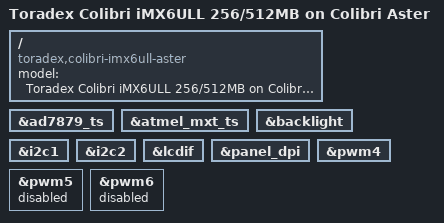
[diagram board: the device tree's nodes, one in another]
// SPDX-License-Identifier: GPL-2.0-or-later OR MIT
/*
 * Copyright 2017-2022 Toradex
 */

/dts-v1/;

#include "imx6ull-colibri-nonwifi.dtsi"
#include "imx6ull-colibri-aster.dtsi"

/ {
	model = "Toradex Colibri iMX6ULL 256/512MB on Colibri Aster";
	compatible = "toradex,colibri-imx6ull-aster",
		     "toradex,colibri-imx6ull",
		     "fsl,imx6ull";
};

&ad7879_ts {
	status = "okay";
};

&atmel_mxt_ts {
	status = "okay";
};

&backlight {
	status = "okay";
};

&i2c1 {
	status = "okay";
};

&i2c2 {
	status = "okay";
};

&lcdif {
	status = "okay";
};

&panel_dpi {
	status = "okay";
};

&pwm4 {
	status = "okay";
};

/* PWM <B> */
&pwm5 {
	/* Pin already used by atmel_mxt_ts touchscreen */
	status = "disabled";
};

/* PWM <C> */
&pwm6 {
	/* Pin already used by atmel_mxt_ts touchscreen */
	status = "disabled";
};
